# FIXTURE register map
Registers are 16-bit, read-only, reset 0x0 unless marked. A register's access mark holds for its fields unless they carry their own. Offsets are from the block's base; lines under a group give offsets from that group; [hi:lo] are bit positions; {n}, {i} and the like mark numbered series; 'fields as' and 'values as' point back to an identical list; <NAME> marks a mode.

## Memory map
0xF0001000 ZETA blocks up to offset 0x240 — Sorted after the grouped ones: <tx> & A B &unknown;
0xF0002000 ALPHA
0xF0003000 LATE
0xF0004000 EMPTY

## ZETA — Sorted after the grouped ones: <tx> & A B &unknown;
Base 0xF0001000
0x00 CTRL 32-bit rw reset 0x5 — Control over two lines
  [9] PATH
    0=OFF; 1=ON; other=DEFAULT; 1=ON_AGAIN
  [8] CH{x} (x=A,B; step 1) — Channel {x}
    0=OFF; 1=ON; other=DEFAULT; 1=ON_AGAIN
  [4] FLAG write-1-clears read-clears
  [3:1] MODE — Named further on in the file
    0=S0 (First choice); 7=S7
  [0] EN — Enable
    0=OFF; 1=ON; other=DEFAULT; 1=ON_AGAIN
{0x10+4i} DATA[{i}] (i=0..3) read-modifies — Data word {i}
  [31:0] VALUE wo
{0x14+4i} R{i} (i=3..5)
0x30 L{x} (x=a-c; step 0x4)
0x38 U{x} (x=x; step 0x4)
0x40 ALIAS 32-bit rw reset 0x5 — Like CTRL, at <0x40>
  fields as CTRL
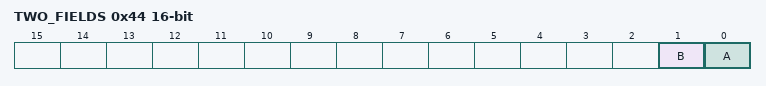
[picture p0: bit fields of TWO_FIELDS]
0x44 TWO_FIELDS
  [1] B, [0] A
0x48 ODD write-once reset not defined
{0x100+0x20*i} CL{i} (i=0..1) group — Cluster {i}
  0x00 X 8-bit rw-once
    [1:0] K
  0x10 SUB group
    0x04 Y 8-bit rw-once

## ALPHA
Base 0xF0002000
0x08 ONLY group
  0x00 Q 32-bit rw

## LATE
Base 0xF0003000
0x00 M 32-bit rw
  [2:0] SEL
    0=S0 (First choice); 7=S7
